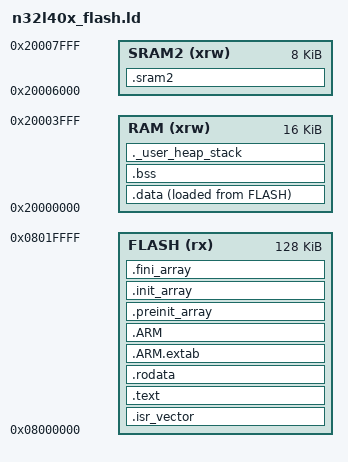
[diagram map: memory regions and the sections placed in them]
/*
 * Linker script for Nations N32L403KBQ7 Cortex-M4F.
 * N32L403KBQ7 SRAM is split into two non-contiguous banks:
 *   SRAM1: 0x20000000..0x20003FFF (16K)
 *   SRAM2: 0x20006000..0x20007FFF (8K)
 */

ENTRY(Reset_Handler)

_estack = ORIGIN(RAM) + LENGTH(RAM);
_Min_Heap_Size = 0x200;
_Min_Stack_Size = 0x1000;

MEMORY
{
  FLASH (rx)   : ORIGIN = 0x08000000, LENGTH = 128K
  RAM   (xrw)  : ORIGIN = 0x20000000, LENGTH = 16K
  SRAM2 (xrw)  : ORIGIN = 0x20006000, LENGTH = 8K
}

SECTIONS
{
  .isr_vector :
  {
    . = ALIGN(4);
    KEEP(*(.isr_vector))
    . = ALIGN(4);
  } > FLASH

  .text :
  {
    . = ALIGN(4);
    *(.text)
    *(.text*)
    *(.glue_7)
    *(.glue_7t)
    *(.eh_frame)

    KEEP(*(.init))
    KEEP(*(.fini))

    . = ALIGN(4);
    __fsymtab_start = .;
    KEEP(*(FSymTab))
    __fsymtab_end = .;

    . = ALIGN(4);
    __vsymtab_start = .;
    KEEP(*(VSymTab))
    __vsymtab_end = .;

    . = ALIGN(4);
    __rt_init_start = .;
    KEEP(*(SORT(.rti_fn*)))
    __rt_init_end = .;

    . = ALIGN(4);
    _etext = .;
  } > FLASH

  .rodata :
  {
    . = ALIGN(4);
    *(.rodata)
    *(.rodata*)
    . = ALIGN(4);
  } > FLASH

  .ARM.extab :
  {
    *(.ARM.extab* .gnu.linkonce.armextab.*)
  } > FLASH

  .ARM :
  {
    __exidx_start = .;
    *(.ARM.exidx*)
    __exidx_end = .;
  } > FLASH

  .preinit_array :
  {
    PROVIDE_HIDDEN(__preinit_array_start = .);
    KEEP(*(.preinit_array*))
    PROVIDE_HIDDEN(__preinit_array_end = .);
  } > FLASH

  .init_array :
  {
    PROVIDE_HIDDEN(__init_array_start = .);
    KEEP(*(SORT(.init_array.*)))
    KEEP(*(.init_array*))
    PROVIDE_HIDDEN(__init_array_end = .);
  } > FLASH

  .fini_array :
  {
    PROVIDE_HIDDEN(__fini_array_start = .);
    KEEP(*(SORT(.fini_array.*)))
    KEEP(*(.fini_array*))
    PROVIDE_HIDDEN(__fini_array_end = .);
  } > FLASH

  _sidata = LOADADDR(.data);

  .data :
  {
    . = ALIGN(4);
    _sdata = .;
    *(.data)
    *(.data*)
    . = ALIGN(4);
    _edata = .;
  } > RAM AT > FLASH

  . = ALIGN(4);
  .bss :
  {
    _sbss = .;
    __bss_start__ = _sbss;
    *(.bss)
    *(.bss*)
    *(COMMON)
    . = ALIGN(4);
    _ebss = .;
    __bss_end__ = _ebss;
  } > RAM

  .sram2 (NOLOAD) :
  {
    . = ALIGN(8);
    _ssram2 = .;
    *(.sram2)
    *(.sram2*)
    . = ALIGN(8);
    _esram2 = .;
  } > SRAM2

  ._user_heap_stack :
  {
    . = ALIGN(8);
    PROVIDE(end = .);
    PROVIDE(_end = .);
    . = . + _Min_Heap_Size;
    . = . + _Min_Stack_Size;
    . = ALIGN(8);
  } > RAM

  /DISCARD/ :
  {
    libc.a(*)
    libm.a(*)
    libgcc.a(*)
  }

  .ARM.attributes 0 : { *(.ARM.attributes) }
}
